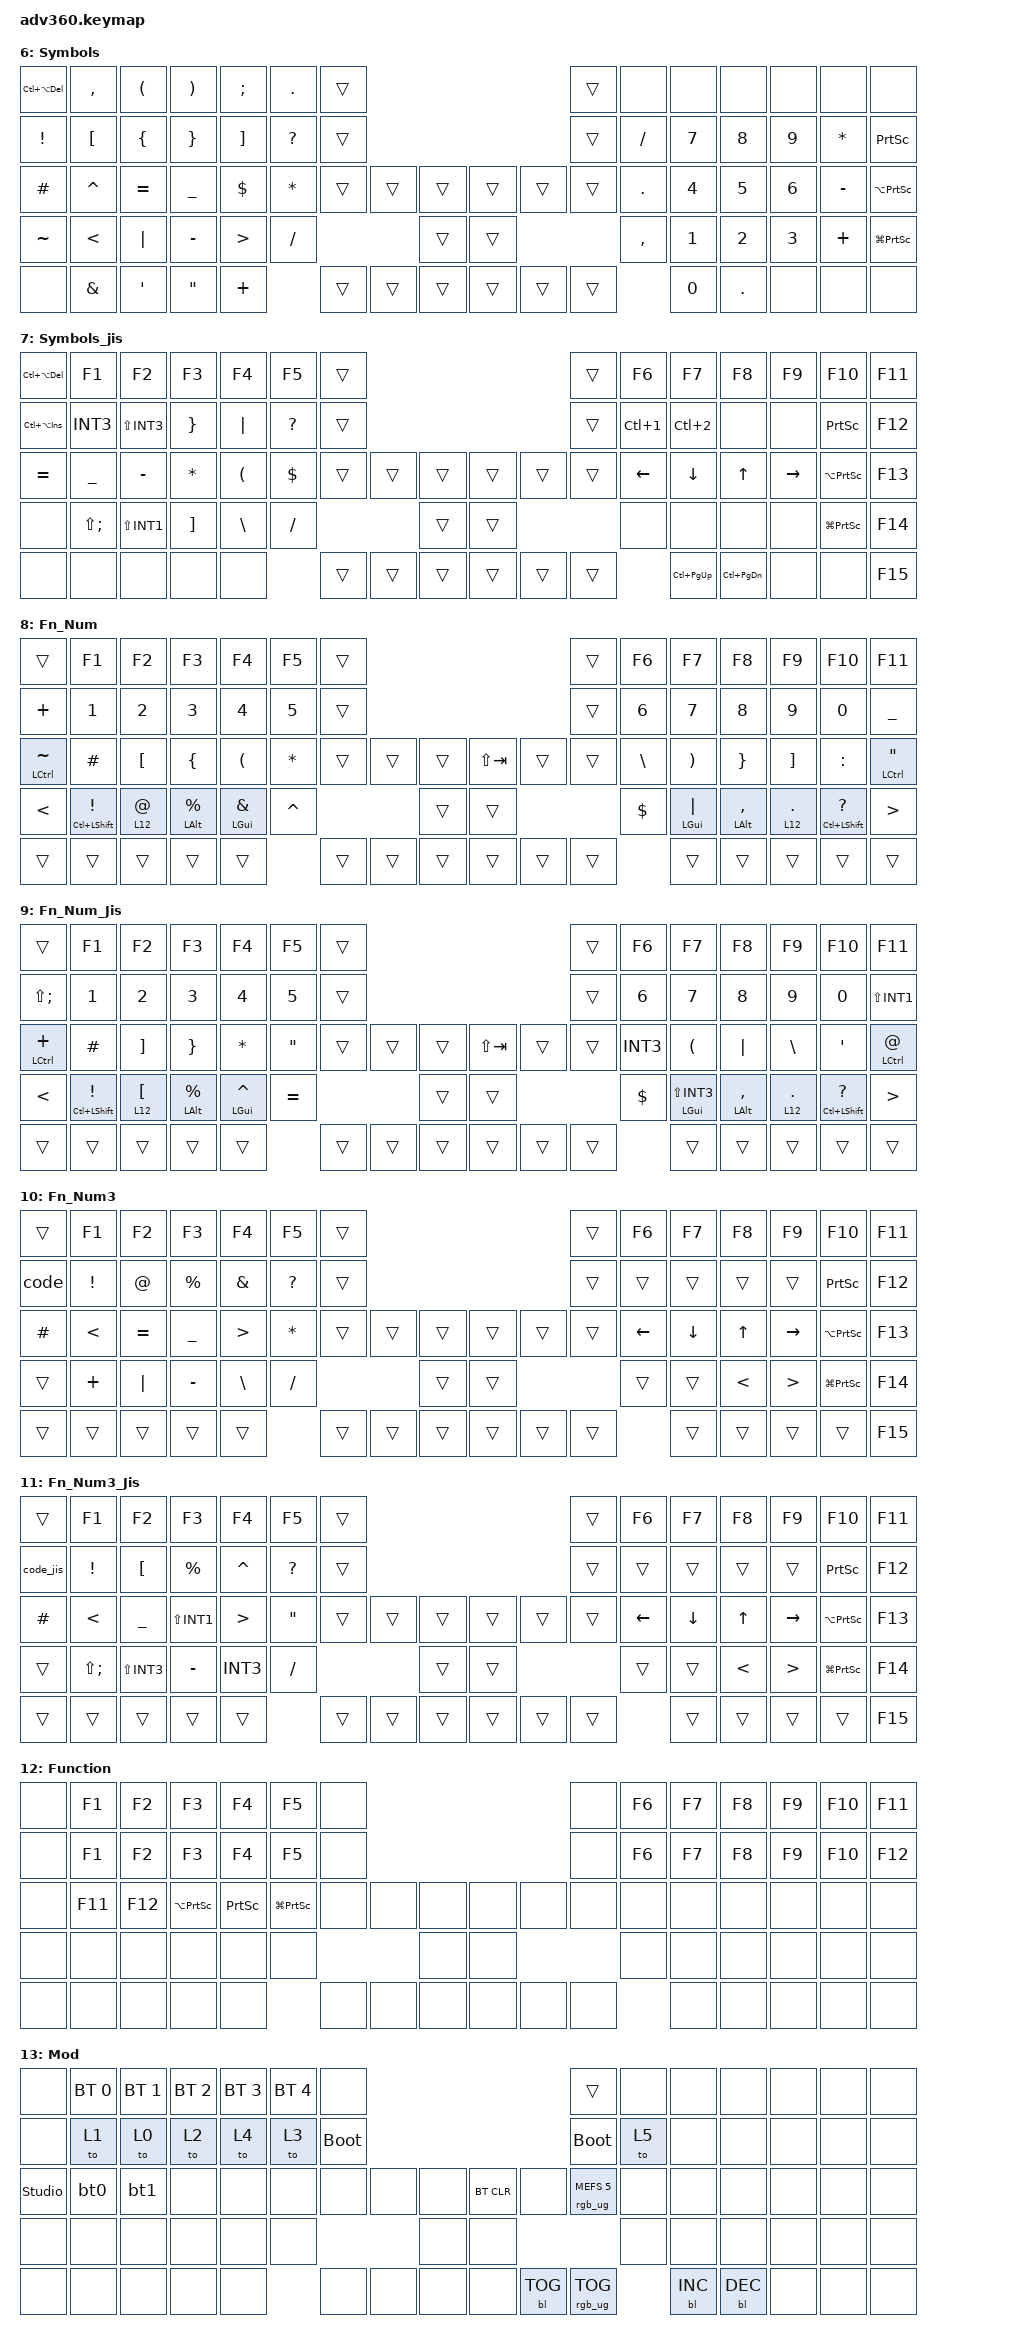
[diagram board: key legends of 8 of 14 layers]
#include <dt-bindings/zmk/stp.h>
#include <behaviors.dtsi>
#include <dt-bindings/zmk/backlight.h>
#include <dt-bindings/zmk/bt.h>
#include <dt-bindings/zmk/keys.h>
#include <dt-bindings/zmk/pointing.h>
#include <dt-bindings/zmk/rgb.h>

&sk {
    quick-release;
    release-after-ms = <300>;
};

/ {
    behaviors {
        #include "macros.dtsi"
      #include "version.dtsi"

        hml: hml {
            compatible = "zmk,behavior-hold-tap";
            label = "HML";
            bindings = <&kp>, <&kp>;

            #binding-cells = <2>;
            hold-trigger-key-positions = <7 8 9 10 11 12 13 21 22 23 24 25 26 27 37 38 39 40 41 42 43 44 45 53 54 55 56 57 58 59 68 69 70 71 72 73 74 75>;
            flavor = "balanced";
            hold-trigger-on-release;
            tapping-term-ms = <200>;
            require-prior-idle-ms = <150>;
            quick-tap-ms = <200>;
        };

        hmr: hmr {
            compatible = "zmk,behavior-hold-tap";
            label = "HMR";
            bindings = <&kp>, <&kp>;

            #binding-cells = <2>;
            flavor = "balanced";
            hold-trigger-on-release;
            tapping-term-ms = <200>;
            hold-trigger-key-positions = <0 1 2 3 4 5 6 14 15 16 17 18 19 20 28 29 30 31 32 33 34 35 36 46 47 48 49 50 51 52 60 61 62 63 64 65 66 67>;
            require-prior-idle-ms = <150>;
            quick-tap-ms = <200>;
        };

        hml_mod: hml_mod {
            compatible = "zmk,behavior-hold-tap";
            label = "HML_MOD";
            bindings = <&mo>, <&kp>;

            #binding-cells = <2>;
            hold-trigger-key-positions = <7 8 9 10 11 12 13 21 22 23 24 25 26 27 37 38 39 40 41 42 43 44 45 53 54 55 56 57 58 59 68 69 70 71 72 73 74 75>;
            flavor = "balanced";
            hold-trigger-on-release;
            tapping-term-ms = <280>;
            quick-tap-ms = <200>;
            require-prior-idle-ms = <150>;
        };

        hmr_mod: hmr_mod {
            compatible = "zmk,behavior-hold-tap";
            label = "HMR_MOD";
            bindings = <&mo>, <&kp>;

            #binding-cells = <2>;
            flavor = "balanced";
            hold-trigger-on-release;
            tapping-term-ms = <280>;
            hold-trigger-key-positions = <0 1 2 3 4 5 6 14 15 16 17 18 19 20 28 29 30 31 32 33 34 35 36 46 47 48 49 50 51 52 60 61 62 63 64 65 66 67>;
            quick-tap-ms = <200>;
            require-prior-idle-ms = <150>;
        };

        mj_bp: mj_bp {
            compatible = "zmk,behavior-mod-morph";
            label = "MJ_BP";
            bindings = <&kp INT3>, <&kp LS(INT3)>;

            #binding-cells = <0>;
            mods = <(MOD_LSFT|MOD_RSFT)>;
        };

        mj_mu: mj_mu {
            compatible = "zmk,behavior-mod-morph";
            label = "MJ_MU";
            bindings = <&kp MINUS>, <&kp LS(INT1)>;

            #binding-cells = <0>;
            mods = <(MOD_LSFT|MOD_RSFT)>;
        };

        mj_gt: mj_gt {
            compatible = "zmk,behavior-mod-morph";
            label = "MJ_GT";
            bindings = <&kp LBRC>, <&kp PLUS>;

            #binding-cells = <0>;
            mods = <(MOD_LSFT|MOD_RSFT)>;
        };

        mj_ep: mj_ep {
            compatible = "zmk,behavior-mod-morph";
            label = "MJ_EP";
            bindings = <&kp UNDER>, <&kp LS(SEMI)>;

            #binding-cells = <0>;
            mods = <(MOD_LSFT|MOD_RSFT)>;
        };

        mj_qd: mj_qd {
            compatible = "zmk,behavior-mod-morph";
            label = "MJ_QD";
            bindings = <&kp AMPS>, <&kp AT>;

            #binding-cells = <0>;
            mods = <(MOD_LSFT|MOD_RSFT)>;
        };

        mj_sc: mj_sc {
            compatible = "zmk,behavior-mod-morph";
            label = "MJ_SC";
            bindings = <&kp SEMI>, <&kp SQT>;

            #binding-cells = <0>;
            mods = <(MOD_LSFT|MOD_RSFT)>;
        };

        mm_n1: mm_n1 {
            compatible = "zmk,behavior-mod-morph";
            label = "MM_N1";
            bindings = <&kp HASH>, <&kp N1>;

            #binding-cells = <0>;
            mods = <(MOD_LSFT|MOD_RSFT)>;
        };

        mm_n2: mm_n2 {
            compatible = "zmk,behavior-mod-morph";
            label = "MM_N2";
            bindings = <&kp LBKT>, <&kp N2>;

            #binding-cells = <0>;
            mods = <(MOD_LSFT|MOD_RSFT)>;
        };

        mm_n3: mm_n3 {
            compatible = "zmk,behavior-mod-morph";
            label = "MM_N3";
            bindings = <&kp LBRC>, <&kp N3>;

            #binding-cells = <0>;
            mods = <(MOD_LSFT|MOD_RSFT)>;
        };

        mm_n4: mm_n4 {
            compatible = "zmk,behavior-mod-morph";
            label = "MM_N4";
            bindings = <&kp LPAR>, <&kp N4>;

            #binding-cells = <0>;
            mods = <(MOD_LSFT|MOD_RSFT)>;
        };

        mm_n5: mm_n5 {
            compatible = "zmk,behavior-mod-morph";
            label = "MM_N5";
            bindings = <&kp STAR>, <&kp N5>;

            #binding-cells = <0>;
            mods = <(MOD_LSFT|MOD_RSFT)>;
        };

        mm_n6: mm_n6 {
            compatible = "zmk,behavior-mod-morph";
            label = "MM_N6";
            bindings = <&kp CARET>, <&kp N6>;

            #binding-cells = <0>;
            mods = <(MOD_LSFT|MOD_RSFT)>;
        };

        mm_n7: mm_n7 {
            compatible = "zmk,behavior-mod-morph";
            label = "MM_N7";
            bindings = <&kp RPAR>, <&kp N7>;

            #binding-cells = <0>;
            mods = <(MOD_LSFT|MOD_RSFT)>;
        };

        mm_n8: mm_n8 {
            compatible = "zmk,behavior-mod-morph";
            label = "MM_N8";
            bindings = <&kp RBRC>, <&kp N8>;

            #binding-cells = <0>;
            mods = <(MOD_LSFT|MOD_RSFT)>;
        };

        mm_n9: mm_n9 {
            compatible = "zmk,behavior-mod-morph";
            label = "MM_N9";
            bindings = <&kp RBKT>, <&kp N9>;

            #binding-cells = <0>;
            mods = <(MOD_LSFT|MOD_RSFT)>;
        };

        mm_n0: mm_n0 {
            compatible = "zmk,behavior-mod-morph";
            label = "MM_N0";
            bindings = <&kp DLLR>, <&kp N0>;

            #binding-cells = <0>;
            mods = <(MOD_LSFT|MOD_RSFT)>;
        };

        mm_ea: mm_ea {
            compatible = "zmk,behavior-mod-morph";
            label = "MM_EA";
            bindings = <&kp EXCL>, <&kp AT>;

            #binding-cells = <0>;
            mods = <(MOD_LSFT|MOD_RSFT)>;
        };

        mm_pa: mm_pa {
            compatible = "zmk,behavior-mod-morph";
            label = "MM_PA";
            bindings = <&kp PRCNT>, <&kp AMPS>;

            #binding-cells = <0>;
            mods = <(MOD_LSFT|MOD_RSFT)>;
        };

        mj_n1: mj_n1 {
            compatible = "zmk,behavior-mod-morph";
            label = "MJ_N1";
            bindings = <&kp HASH>, <&kp N1>;

            #binding-cells = <0>;
            mods = <(MOD_LSFT|MOD_RSFT)>;
        };

        mj_n2: mj_n2 {
            compatible = "zmk,behavior-mod-morph";
            label = "MJ_N2";
            bindings = <&kp RBKT>, <&kp N2>;

            #binding-cells = <0>;
            mods = <(MOD_LSFT|MOD_RSFT)>;
        };

        mj_n3: mj_n3 {
            compatible = "zmk,behavior-mod-morph";
            label = "MJ_N3";
            bindings = <&kp RBRC>, <&kp N3>;

            #binding-cells = <0>;
            mods = <(MOD_LSFT|MOD_RSFT)>;
        };

        mj_n4: mj_n4 {
            compatible = "zmk,behavior-mod-morph";
            label = "MJ_N4";
            bindings = <&kp STAR>, <&kp N4>;

            #binding-cells = <0>;
            mods = <(MOD_LSFT|MOD_RSFT)>;
        };

        mj_n5: mj_n5 {
            compatible = "zmk,behavior-mod-morph";
            label = "MJ_N5";
            bindings = <&kp DQT>, <&kp N5>;

            #binding-cells = <0>;
            mods = <(MOD_LSFT|MOD_RSFT)>;
        };

        mj_n6: mj_n6 {
            compatible = "zmk,behavior-mod-morph";
            label = "MJ_N6";
            bindings = <&kp EQUAL>, <&kp N6>;

            #binding-cells = <0>;
            mods = <(MOD_LSFT|MOD_RSFT)>;
        };

        mj_n7: mj_n7 {
            compatible = "zmk,behavior-mod-morph";
            label = "MJ_N7";
            bindings = <&kp LPAR>, <&kp N7>;

            #binding-cells = <0>;
            mods = <(MOD_LSFT|MOD_RSFT)>;
        };

        mj_n8: mj_n8 {
            compatible = "zmk,behavior-mod-morph";
            label = "MJ_N8";
            bindings = <&kp PIPE>, <&kp N8>;

            #binding-cells = <0>;
            mods = <(MOD_LSFT|MOD_RSFT)>;
        };

        mj_n9: mj_n9 {
            compatible = "zmk,behavior-mod-morph";
            label = "MJ_N9";
            bindings = <&kp BSLH>, <&kp N9>;

            #binding-cells = <0>;
            mods = <(MOD_LSFT|MOD_RSFT)>;
        };

        mj_n0: mj_n0 {
            compatible = "zmk,behavior-mod-morph";
            label = "MJ_N0";
            bindings = <&kp DLLR>, <&kp N0>;

            #binding-cells = <0>;
            mods = <(MOD_LSFT|MOD_RSFT)>;
        };

        mj_ea: mj_ea {
            compatible = "zmk,behavior-mod-morph";
            label = "MJ_EA";
            bindings = <&kp EXCL>, <&kp LBKT>;

            #binding-cells = <0>;
            mods = <(MOD_LSFT|MOD_RSFT)>;
        };

        mj_pa: mj_pa {
            compatible = "zmk,behavior-mod-morph";
            label = "MJ_PA";
            bindings = <&kp PRCNT>, <&kp CARET>;

            #binding-cells = <0>;
            mods = <(MOD_LSFT|MOD_RSFT)>;
        };

        mtl: mtl {
            compatible = "zmk,behavior-hold-tap";
            label = "MTL";
            bindings = <&kp>, <&to>;

            #binding-cells = <2>;
            tapping-term-ms = <200>;
        };

        aj_n2: aj_n2 {
            compatible = "zmk,behavior-mod-morph";
            label = "AJ_N2";
            bindings = <&kp N2>, <&kp LBKT>;

            #binding-cells = <0>;
            mods = <(MOD_LSFT|MOD_RSFT)>;
        };

        aj_n6: aj_n6 {
            compatible = "zmk,behavior-mod-morph";
            label = "AJ_N6";
            bindings = <&kp N6>, <&kp EQUAL>;

            #binding-cells = <0>;
            mods = <(MOD_LSFT|MOD_RSFT)>;
        };

        aj_n7: aj_n7 {
            compatible = "zmk,behavior-mod-morph";
            label = "AJ_N7";
            bindings = <&kp N7>, <&kp CARET>;

            #binding-cells = <0>;
            mods = <(MOD_LSFT|MOD_RSFT)>;
        };

        aj_n8: aj_n8 {
            compatible = "zmk,behavior-mod-morph";
            label = "AJ_N8";
            bindings = <&kp N8>, <&kp DQT>;

            #binding-cells = <0>;
            mods = <(MOD_LSFT|MOD_RSFT)>;
        };

        aj_n9: aj_n9 {
            compatible = "zmk,behavior-mod-morph";
            label = "AJ_N9";
            bindings = <&kp N9>, <&kp STAR>;

            #binding-cells = <0>;
            mods = <(MOD_LSFT|MOD_RSFT)>;
        };

        aj_n0: aj_n0 {
            compatible = "zmk,behavior-mod-morph";
            label = "AJ_N0";
            bindings = <&kp N0>, <&kp LPAR>;

            #binding-cells = <0>;
            mods = <(MOD_LSFT|MOD_RSFT)>;
        };

        hml_mod2: hml_mod2 {
            compatible = "zmk,behavior-hold-tap";
            label = "HML_MOD2";
            bindings = <&mo>, <&kp>;

            #binding-cells = <2>;
            hold-trigger-key-positions = <7 8 9 10 11 12 13 21 22 23 24 25 26 27 37 38 39 40 41 42 43 44 45 53 54 55 56 57 58 59 68 69 70 71 72 73 74 75>;
            flavor = "balanced";
            hold-trigger-on-release;
            tapping-term-ms = <280>;
            quick-tap-ms = <175>;
            require-prior-idle-ms = <150>;
            hold-while-undecided;
        };

        hmr_mod2: hmr_mod2 {
            compatible = "zmk,behavior-hold-tap";
            label = "HMR_MOD2";
            bindings = <&mo>, <&kp>;

            #binding-cells = <2>;
            flavor = "balanced";
            hold-trigger-on-release;
            tapping-term-ms = <280>;
            hold-trigger-key-positions = <0 1 2 3 4 5 6 14 15 16 17 18 19 20 28 29 30 31 32 33 34 35 36 46 47 48 49 50 51 52 60 61 62 63 64 65 66 67>;
            quick-tap-ms = <175>;
            require-prior-idle-ms = <150>;
            hold-while-undecided;
        };

        hm: hm {
            compatible = "zmk,behavior-hold-tap";
            label = "HM";
            bindings = <&mo>, <&kp>;

            #binding-cells = <2>;
            hold-trigger-key-positions = <7 8 9 10 11 12 13 21 22 23 24 25 26 27 39 40 41 42 43 44 45 54 55 56 57 58 59 71 72 73 74 75 0 1 2 3 4 5 6 14 15 16 17 18 19 20 28 29 30 31 32 33 34 46 47 48 49 50 51 60 61 62 63 64>;
            tapping-term-ms = <200>;
            require-prior-idle-ms = <150>;
            flavor = "balanced";
            hold-trigger-on-release;
        };

        mm_lp: mm_lp {
            compatible = "zmk,behavior-mod-morph";
            label = "MM_LP";
            bindings = <&kp LT>, <&kp PRCNT>;

            #binding-cells = <0>;
            mods = <(MOD_LSFT|MOD_RSFT)>;
        };

        mm_ga: mm_ga {
            compatible = "zmk,behavior-mod-morph";
            label = "MM_GA";
            bindings = <&kp GT>, <&kp AMPS>;

            #binding-cells = <0>;
            mods = <(MOD_LSFT|MOD_RSFT)>;
        };

        mj_ga: mj_ga {
            compatible = "zmk,behavior-mod-morph";
            label = "MJ_GA";
            bindings = <&kp GT>, <&kp CARET>;

            #binding-cells = <0>;
            mods = <(MOD_LSFT|MOD_RSFT)>;
        };

        cc: cc {
            compatible = "zmk,behavior-mod-morph";
            label = "CC";
            bindings = <&kp COMMA>, <&kp COMMA>;

            #binding-cells = <0>;
            mods = <(MOD_LSFT|MOD_RSFT)>;
        };

        dd: dd {
            compatible = "zmk,behavior-mod-morph";
            label = "DD";
            bindings = <&kp DOT>, <&kp DOT>;

            #binding-cells = <0>;
            mods = <(MOD_LSFT|MOD_RSFT)>;
        };

        hmr_cc: hmr_cc {
            compatible = "zmk,behavior-hold-tap";
            label = "HMR_CC";
            bindings = <&kp>, <&cc>;

            #binding-cells = <2>;
            flavor = "balanced";
            hold-trigger-on-release;
            tapping-term-ms = <200>;
            hold-trigger-key-positions = <0 1 2 3 4 5 6 14 15 16 17 18 19 20 28 29 30 31 32 33 34 35 36 46 47 48 49 50 51 52 60 61 62 63 64 65 66 67>;
            require-prior-idle-ms = <150>;
            quick-tap-ms = <200>;
        };

        hmr_dd: hmr_dd {
            compatible = "zmk,behavior-hold-tap";
            label = "HMR_DD";
            bindings = <&kp>, <&dd>;

            #binding-cells = <2>;
            flavor = "balanced";
            hold-trigger-on-release;
            tapping-term-ms = <200>;
            hold-trigger-key-positions = <0 1 2 3 4 5 6 14 15 16 17 18 19 20 28 29 30 31 32 33 34 35 36 46 47 48 49 50 51 52 60 61 62 63 64 65 66 67>;
            require-prior-idle-ms = <150>;
            quick-tap-ms = <200>;
        };

        hmr_sc: hmr_sc {
            compatible = "zmk,behavior-hold-tap";
            label = "HMR_SC";
            bindings = <&kp>, <&mj_sc>;

            #binding-cells = <2>;
            flavor = "balanced";
            hold-trigger-on-release;
            tapping-term-ms = <200>;
            hold-trigger-key-positions = <0 1 2 3 4 5 6 14 15 16 17 18 19 20 28 29 30 31 32 33 34 35 36 46 47 48 49 50 51 52 60 61 62 63 64 65 66 67>;
            require-prior-idle-ms = <150>;
            quick-tap-ms = <200>;
        };

        custom_shift: custom_shift {
            compatible = "zmk,behavior-tap-dance";
            label = "CUSTOM_SHIFT";
            #binding-cells = <0>;
            bindings = <&sk LSHIFT>, <&caps_word>;
        };

        ins_com: ins_com {
            compatible = "zmk,behavior-mod-morph";
            label = "INS_COM";
            bindings = <&kp INS>, <&kp COMMA>;

            #binding-cells = <0>;
            mods = <(MOD_LSFT|MOD_RSFT)>;
        };

        del_dot: del_dot {
            compatible = "zmk,behavior-mod-morph";
            label = "DEL_DOT";
            bindings = <&kp DEL>, <&kp DOT>;

            #binding-cells = <0>;
            mods = <(MOD_LSFT|MOD_RSFT)>;
        };

        hml_gt: hml_gt {
            compatible = "zmk,behavior-hold-tap";
            label = "HML_GT";
            bindings = <&kp>, <&mj_gt>;

            #binding-cells = <2>;
            flavor = "balanced";
            hold-trigger-on-release;
            tapping-term-ms = <200>;
            require-prior-idle-ms = <150>;
            quick-tap-ms = <200>;
            hold-trigger-key-positions = <7 8 9 10 11 12 13 21 22 23 24 25 26 27 37 38 39 40 41 42 43 44 45 53 54 55 56 57 58 59 68 69 70 71 72 73 74 75>;
        };

        hmr_qd: hmr_qd {
            compatible = "zmk,behavior-hold-tap";
            label = "HMR_QD";
            bindings = <&kp>, <&mj_qd>;

            #binding-cells = <2>;
            flavor = "balanced";
            hold-trigger-on-release;
            tapping-term-ms = <200>;
            hold-trigger-key-positions = <0 1 2 3 4 5 6 14 15 16 17 18 19 20 28 29 30 31 32 33 34 35 36 46 47 48 49 50 51 52 60 61 62 63 64 65 66 67>;
            require-prior-idle-ms = <150>;
            quick-tap-ms = <200>;
        };

        up_lt: up_lt {
            compatible = "zmk,behavior-mod-morph";
            label = "UP_LT";
            bindings = <&kp UP>, <&kp LT>;

            #binding-cells = <0>;
            mods = <(MOD_LSFT|MOD_RSFT)>;
        };

        lc_gt: lc_gt {
            compatible = "zmk,behavior-mod-morph";
            label = "LC_GT";
            bindings = <&mkp LCLK>, <&kp GT>;

            #binding-cells = <0>;
            mods = <(MOD_LSFT|MOD_RSFT)>;
        };

        pgdn_prcnt: pgdn_prcnt {
            compatible = "zmk,behavior-mod-morph";
            label = "PGDN_PRCNT";
            bindings = <&kp PG_DN>, <&kp PRCNT>;

            #binding-cells = <0>;
            mods = <(MOD_LSFT|MOD_RSFT)>;
        };

        left_amps: left_amps {
            compatible = "zmk,behavior-mod-morph";
            label = "LEFT_AMPS";
            bindings = <&kp LEFT>, <&kp AMPS>;

            #binding-cells = <0>;
            mods = <(MOD_LSFT|MOD_RSFT)>;
        };

        mj_left_amps: mj_left_amps {
            compatible = "zmk,behavior-mod-morph";
            label = "MJ_LEFT_AMPS";
            bindings = <&kp LEFT>, <&kp CARET>;

            #binding-cells = <0>;
            mods = <(MOD_LSFT|MOD_RSFT)>;
        };
    };

    macros {
        bt0: bt0 {
            compatible = "zmk,behavior-macro";
            #binding-cells = <0>;
            bindings =
                <&macro_press>,
                <&kp F13>,
                <&macro_release>,
                <&macro_wait_time 50>,
                <&macro_press>,
                <&bt BT_SEL 0>,
                <&macro_release>;

            label = "BT0";
        };

        bt1: bt1 {
            compatible = "zmk,behavior-macro";
            #binding-cells = <0>;
            bindings =
                <&macro_press>,
                <&kp F14>,
                <&macro_release>,
                <&macro_wait_time 50>,
                <&macro_press>,
                <&bt BT_SEL 1>,
                <&macro_release>;

            label = "BT1";
        };

        code: code {
            compatible = "zmk,behavior-macro";
            #binding-cells = <0>;
            bindings = <&kp GRAVE &kp GRAVE &kp GRAVE>;
            label = "CODE";
        };

        code_jis: code_jis {
            compatible = "zmk,behavior-macro";
            #binding-cells = <0>;
            bindings = <&kp LBRC &kp LBRC &kp LBRC>;
            label = "CODE_JIS";
        };

        d_colon: double_colon {
            compatible = "zmk,behavior-macro";
            #binding-cells = <0>;
            bindings = <&kp COLON &kp COLON>;
            label = "DOUBLE_COLON";
        };

        d_colon_jis: double_colon_jis {
            compatible = "zmk,behavior-macro";
            #binding-cells = <0>;
            bindings = <&kp SQT &kp SQT>;
            label = "DOUBLE_COLON_JIS";
        };

        pren: pren {
            compatible = "zmk,behavior-macro";
            #binding-cells = <0>;
            bindings = <&kp LPAR &kp RPAR>;
            label = "PREN";
        };

        pren_jis: pren_jis {
            compatible = "zmk,behavior-macro";
            #binding-cells = <0>;
            bindings = <&kp STAR &kp LPAR>;
            label = "PREN_JIS";
        };

        brc: brc {
            compatible = "zmk,behavior-macro";
            #binding-cells = <0>;
            bindings = <&kp LBRC &kp RBRC>;
            label = "BRC";
        };

        brc_jis: brc_jis {
            compatible = "zmk,behavior-macro";
            #binding-cells = <0>;
            bindings = <&kp RBRC &kp PIPE>;
            label = "BRC_JIS";
        };

        bkt: bkt {
            compatible = "zmk,behavior-macro";
            #binding-cells = <0>;
            bindings = <&kp LBKT &kp RBKT>;
            label = "BKT";
        };

        bkt_jis: bkt_jis {
            compatible = "zmk,behavior-macro";
            #binding-cells = <0>;
            bindings = <&kp RBKT &kp BSLH>;
            label = "BKT_JIS";
        };
    };

    combos { compatible = "zmk,combos"; };

    keymap {
        compatible = "zmk,keymap";

        base_reverse_org {
            display-name = "Base_reverse_Org";
            bindings = <
&mm_ea            &mm_n1             &mm_n2                    &mm_n3       &mm_n4       &mm_n5         &kp PSCRN                                                              &mo 13     &mm_n6         &mm_n7       &mm_n8           &mm_n9                      &mm_n0                &kp BSLH
&kp EQUAL         &kp Q              &kp W                     &kp E        &kp R        &kp T          &kp INS                                                                &kp DEL    &kp Y          &kp U        &kp I            &kp O                       &kp P                 &kp MINUS
&hml LCTRL GRAVE  &kp A              &kp S                     &kp D        &kp F        &kp G          &none      &kp LCTRL  &kp LALT       &kp TAB                &kp ESC    &none      &kp H          &kp J        &kp K            &kp L                       &kp SEMI              &hmr LCTRL SQT
&custom_shift     &hml LC(LSHIFT) Z  &hml LS(LA(LG(LCTRL))) X  &hml LALT C  &hml LGUI V  &hml_mod 12 B                        &kp LGUI       &kp LS(LA(LG(LCTRL)))                        &hmr_mod 12 N  &hmr LGUI M  &hmr LALT COMMA  &hmr LS(LA(LG(LCTRL))) DOT  &hmr LC(LSHIFT) FSLH  &custom_shift
&mo 12            &kp PG_UP          &kp PAGE_DOWN             &kp LEFT     &kp RIGHT                   &kp BSPC   &mo 8      &kp LANG2      &kp LANG1              &kp ENTER  &kp SPACE                 &kp DOWN     &up_lt           &lc_gt                      &mkp RCLK             &mo 12
            >;
        };

        base_reverse {
            display-name = "Base_reverse";
            bindings = <
&mm_ea            &mm_n1         &mm_n2       &mm_n3      &mm_n4     &mm_n5  &kp PSCRN                                                                  &mo 13     &mm_n6  &mm_n7    &mm_n8  &mm_n9  &mm_n0            &kp BSLH
&kp EQUAL         &kp Q          &kp W        &kp E       &kp R      &kp T   &kp INS                                                                    &kp DEL    &kp Y   &kp U     &kp I   &kp O   &kp P             &kp MINUS
&hml LCTRL GRAVE  &kp A          &kp S        &kp D       &kp F      &kp G   &kp LT     &kp LCTRL      &kp LALT       &kp TAB                &kp ESC    &kp GT     &kp H   &kp J     &kp K   &kp L   &kp SEMI          &hmr LCTRL SQT
&custom_shift     &hml LSHIFT Z  &kp X        &kp C       &kp V      &kp B                             &kp LGUI       &kp LS(LA(LG(LCTRL)))                        &kp N   &kp M     &cc     &dd     &hmr LSHIFT FSLH  &custom_shift
&mo 12            &kp PG_UP      &pgdn_prcnt  &left_amps  &kp RIGHT          &kp BSPC   &custom_shift  &kp LANG2      &kp LANG1              &kp ENTER  &kp SPACE          &kp DOWN  &up_lt  &lc_gt  &mkp RCLK         &mo 12
            >;
        };

        default_layer {
            display-name = "Base";
            bindings = <
&kp DEL           &kp N1             &kp N2                    &kp N3       &kp N4       &kp N5         &kp PSCRN                                                              &mo 13     &kp N6         &kp N7       &kp N8           &kp N9                      &kp N0                &kp BSLH
&kp EQUAL         &kp Q              &kp W                     &kp E        &kp R        &kp T          &kp INS                                                                &kp DEL    &kp Y          &kp U        &kp I            &kp O                       &kp P                 &kp MINUS
&hml LCTRL GRAVE  &kp A              &kp S                     &kp D        &kp F        &kp G          &none      &kp LCTRL  &kp LALT       &kp TAB                &kp ESC    &none      &kp H          &kp J        &kp K            &kp L                       &kp SEMI              &hmr LCTRL SQT
&custom_shift     &hml LC(LSHIFT) Z  &hml LS(LA(LG(LCTRL))) X  &hml LALT C  &hml LGUI V  &hml_mod 12 B                        &kp LGUI       &kp LS(LA(LG(LCTRL)))                        &hmr_mod 12 N  &hmr LGUI M  &hmr LALT COMMA  &hmr LS(LA(LG(LCTRL))) DOT  &hmr LC(LSHIFT) FSLH  &custom_shift
&mo 12            &kp PG_UP          &kp PG_DN                 &kp LEFT     &kp RIGHT                   &kp BSPC   &mo 8      &kp LANG2      &kp LANG1              &kp ENTER  &kp SPACE                 &kp DOWN     &up_lt           &lc_gt                      &mkp RCLK             &mo 12
            >;
        };

        jis_reverse_org {
            display-name = "Jisa_Reverse_Org";
            bindings = <
&mj_ea           &mj_n1             &mj_n2                    &mj_n3       &mj_n4       &mj_n5         &kp PSCRN                                                              &mo 13     &mj_n6         &mj_n7       &mj_n8           &mj_n9                      &mj_n0                &mj_bp
&mj_ep           &kp Q              &kp W                     &kp E        &kp R        &kp T          &kp INS                                                                &kp DEL    &kp Y          &kp U        &kp I            &kp O                       &kp P                 &mj_mu
&hml_gt LCTRL 0  &kp A              &kp S                     &kp D        &kp F        &kp G          &none      &kp LCTRL  &kp LALT       &kp TAB                &kp ESC    &none      &kp H          &kp J        &kp K            &kp L                       &kp SEMI              &hmr_qd LCTRL 0
&custom_shift    &hml LC(LSHIFT) Z  &hml LS(LA(LG(LCTRL))) X  &hml LALT C  &hml LGUI V  &hml_mod 12 B                        &kp LGUI       &kp LS(LA(LG(LCTRL)))                        &hmr_mod 12 N  &hmr LGUI M  &hmr LALT COMMA  &hmr LS(LA(LG(LCTRL))) DOT  &hmr LC(LSHIFT) FSLH  &custom_shift
&mo 12           &kp PG_UP          &kp PAGE_DOWN             &kp LEFT     &kp RIGHT                   &kp BSPC   &mo 9      &kp LANG2      &kp LANG1              &kp ENTER  &kp SPACE                 &kp DOWN     &kp UP           &mkp LCLK                   &mkp RCLK             &mo 12
            >;
        };

        jis_reverse {
            display-name = "Jisa_Reverse";
            bindings = <
&mj_ea           &mj_n1         &mj_n2       &mj_n3         &mj_n4     &mj_n5  &kp PSCRN                                                                  &mo 13     &mj_n6  &mj_n7    &mj_n8  &mj_n9  &mj_n0            &mj_bp
&mj_ep           &kp Q          &kp W        &kp E          &kp R      &kp T   &kp INS                                                                    &kp DEL    &kp Y   &kp U     &kp I   &kp O   &kp P             &mj_mu
&hml_gt LCTRL 0  &kp A          &kp S        &kp D          &kp F      &kp G   &kp LT     &kp LCTRL      &kp LALT       &kp TAB                &kp ESC    &kp GT     &kp H   &kp J     &kp K   &kp L   &kp SEMI          &hmr_qd LCTRL 0
&custom_shift    &hml LSHIFT Z  &kp X        &kp C          &kp V      &kp B                             &kp LGUI       &kp LS(LA(LG(LCTRL)))                        &kp N   &kp M     &cc     &dd     &hmr LSHIFT FSLH  &custom_shift
&mo 12           &kp PG_UP      &pgdn_prcnt  &mj_left_amps  &kp RIGHT          &kp BSPC   &custom_shift  &kp LANG2      &kp LANG1              &kp ENTER  &kp SPACE          &kp DOWN  &up_lt  &lc_gt  &mkp RCLK         &mo 12
            >;
        };

        jis {
            display-name = "Jis";
            bindings = <
&kp DEL          &kp N1             &aj_n2                    &kp N3       &kp N4       &kp N5         &kp PSCRN                                                              &mo 13     &aj_n6         &aj_n7       &aj_n8           &aj_n9                      &aj_n0                &mj_bp
&mj_ep           &kp Q              &kp W                     &kp E        &kp R        &kp T          &kp INS                                                                &kp DEL    &kp Y          &kp U        &kp I            &kp O                       &kp P                 &mj_mu
&hml_gt LCTRL 0  &kp A              &kp S                     &kp D        &kp F        &kp G          &none      &kp LCTRL  &kp LALT       &kp TAB                &kp ESC    &none      &kp H          &kp J        &kp K            &kp L                       &kp SEMI              &hmr_qd LCTRL 0
&custom_shift    &hml LC(LSHIFT) Z  &hml LS(LA(LG(LCTRL))) X  &hml LALT C  &hml LGUI V  &hml_mod 12 B                        &kp LGUI       &kp LS(LA(LG(LCTRL)))                        &hmr_mod 12 N  &hmr LGUI M  &hmr LALT COMMA  &hmr LS(LA(LG(LCTRL))) DOT  &hmr LC(LSHIFT) FSLH  &custom_shift
&mo 12           &kp PG_UP          &kp PG_DN                 &kp LEFT     &kp RIGHT                   &kp BSPC   &mo 9      &kp LANG2      &kp LANG1              &kp ENTER  &kp SPACE                 &kp DOWN     &kp UP           &kp RBKT                    &kp NON_US_BSLH       &mo 12
            >;
        };

        symbols {
            bindings = <
&kp LC(LA(DEL))  &kp COMMA  &kp LPAR   &kp RPAR   &kp SEMI    &kp DOT       &trans                                      &trans  &none      &none   &none    &none   &none      &none
&kp EXCL         &kp LBKT   &kp LBRC   &kp RBRC   &kp RBKT    &kp QUESTION  &trans                                      &trans  &kp FSLH   &kp N7  &kp N8   &kp N9  &kp STAR   &kp PSCRN
&kp HASH         &kp CARET  &kp EQUAL  &kp UNDER  &kp DOLLAR  &kp STAR      &trans  &trans  &trans      &trans  &trans  &trans  &kp DOT    &kp N4  &kp N5   &kp N6  &kp MINUS  &kp LA(PSCRN)
&kp TILDE        &kp LT     &kp PIPE   &kp MINUS  &kp GT      &kp FSLH                      &trans      &trans                  &kp COMMA  &kp N1  &kp N2   &kp N3  &kp PLUS   &kp LG(PSCRN)
&none            &kp AMPS   &kp SQT    &kp DQT    &kp PLUS                  &trans  &trans  &trans      &trans  &trans  &trans             &kp N0  &kp DOT  &none   &none      &none
            >;

            label = "Symbols";
        };

        symbols_jis {
            bindings = <
&kp LC(LA(DEL))  &kp F1        &kp F2        &kp F3    &kp F4    &kp F5        &trans                                      &trans  &kp F6      &kp F7         &kp F8         &kp F9     &kp F10        &kp F11
&kp LC(LA(INS))  &kp INT3      &kp LS(INT3)  &kp RBRC  &kp PIPE  &kp QUESTION  &trans                                      &trans  &kp LC(N1)  &kp LC(N2)     &none          &none      &kp PSCRN      &kp F12
&kp EQUAL        &kp UNDER     &kp MINUS     &kp STAR  &kp LPAR  &kp DLLR      &trans  &trans  &trans      &trans  &trans  &trans  &kp LEFT    &kp DOWN       &kp UP         &kp RIGHT  &kp LA(PSCRN)  &kp F13
&none            &kp LS(SEMI)  &kp LS(INT1)  &kp RBKT  &kp BSLH  &kp FSLH                      &trans      &trans                  &none       &none          &none          &none      &kp LG(PSCRN)  &kp F14
&none            &none         &none         &none     &none                   &trans  &trans  &trans      &trans  &trans  &trans              &kp LC(PG_UP)  &kp LC(PG_DN)  &none      &none          &kp F15
            >;

            label = "Symbols_jis";
        };

        fn_num {
            bindings = <
&trans            &kp F1                &kp F2          &kp F3           &kp F4          &kp F5     &trans                                           &trans  &kp F6    &kp F7          &kp F8           &kp F9           &kp F10                &kp F11
&kp PLUS          &kp N1                &kp N2          &kp N3           &kp N4          &kp N5     &trans                                           &trans  &kp N6    &kp N7          &kp N8           &kp N9           &kp N0                 &kp UNDER
&hml LCTRL TILDE  &kp HASH              &kp LBKT        &kp LBRC         &kp LPAR        &kp STAR   &trans  &trans  &trans      &kp LS(TAB)  &trans  &trans  &kp BSLH  &kp RPAR        &kp RBRC         &kp RBKT         &kp COLON              &hmr LCTRL DQT
&kp LT            &hml LC(LSHIFT) EXCL  &hml_mod 12 AT  &hml LALT PRCNT  &hml LGUI AMPS  &kp CARET                  &trans      &trans                       &kp DLLR  &hmr LGUI PIPE  &hmr LALT COMMA  &hmr_mod 12 DOT  &hmr LC(LSHIFT) QMARK  &kp GT
&trans            &trans                &trans          &trans           &trans                     &trans  &trans  &trans      &trans       &trans  &trans            &trans          &trans           &trans           &trans                 &trans
            >;

            label = "Fn_Num";
        };

        fn_num_jis {
            bindings = <
&trans           &kp F1                &kp F2            &kp F3           &kp F4           &kp F5     &trans                                           &trans  &kp F6    &kp F7              &kp F8           &kp F9           &kp F10                &kp F11
&kp LS(SEMI)     &kp N1                &kp N2            &kp N3           &kp N4           &kp N5     &trans                                           &trans  &kp N6    &kp N7              &kp N8           &kp N9           &kp N0                 &kp LS(INT1)
&hml LCTRL PLUS  &kp HASH              &kp RBKT          &kp RBRC         &kp STAR         &kp DQT    &trans  &trans  &trans      &kp LS(TAB)  &trans  &trans  &kp INT3  &kp LPAR            &kp PIPE         &kp BSLH         &kp SQT                &hmr LCTRL AT
&kp LT           &hml LC(LSHIFT) EXCL  &hml_mod 12 LBKT  &hml LALT PRCNT  &hml LGUI CARET  &kp EQUAL                  &trans      &trans                       &kp DLLR  &hmr LGUI LS(INT3)  &hmr LALT COMMA  &hmr_mod 12 DOT  &hmr LC(LSHIFT) QMARK  &kp GT
&trans           &trans                &trans            &trans           &trans                      &trans  &trans  &trans      &trans       &trans  &trans            &trans              &trans           &trans           &trans                 &trans
            >;

            label = "Fn_Num_Jis";
        };

        fn_num3 {
            label = "Fn_Num3";
            bindings = <
&trans    &kp F1    &kp F2     &kp F3     &kp F4    &kp F5     &trans                                      &trans  &kp F6    &kp F7    &kp F8  &kp F9     &kp F10        &kp F11
&code     &kp EXCL  &kp AT     &kp PRCNT  &kp AMPS  &kp QMARK  &trans                                      &trans  &trans    &trans    &trans  &trans     &kp PSCRN      &kp F12
&kp HASH  &kp LT    &kp EQUAL  &kp UNDER  &kp GT    &kp STAR   &trans  &trans  &trans      &trans  &trans  &trans  &kp LEFT  &kp DOWN  &kp UP  &kp RIGHT  &kp LA(PSCRN)  &kp F13
&trans    &kp PLUS  &kp PIPE   &kp MINUS  &kp BSLH  &kp FSLH                   &trans      &trans                  &trans    &trans    &kp LT  &kp GT     &kp LG(PSCRN)  &kp F14
&trans    &trans    &trans     &trans     &trans               &trans  &trans  &trans      &trans  &trans  &trans            &trans    &trans  &trans     &trans         &kp F15
            >;
        };

        fn_num3_jis {
            label = "Fn_Num3_Jis";
            bindings = <
&trans     &kp F1        &kp F2        &kp F3        &kp F4     &kp F5     &trans                                      &trans  &kp F6    &kp F7    &kp F8  &kp F9     &kp F10        &kp F11
&code_jis  &kp EXCL      &kp LBKT      &kp PRCNT     &kp CARET  &kp QMARK  &trans                                      &trans  &trans    &trans    &trans  &trans     &kp PSCRN      &kp F12
&kp HASH   &kp LT        &kp UNDER     &kp LS(INT1)  &kp GT     &kp DQT    &trans  &trans  &trans      &trans  &trans  &trans  &kp LEFT  &kp DOWN  &kp UP  &kp RIGHT  &kp LA(PSCRN)  &kp F13
&trans     &kp LS(SEMI)  &kp LS(INT3)  &kp MINUS     &kp INT3   &kp FSLH                   &trans      &trans                  &trans    &trans    &kp LT  &kp GT     &kp LG(PSCRN)  &kp F14
&trans     &trans        &trans        &trans        &trans                &trans  &trans  &trans      &trans  &trans  &trans            &trans    &trans  &trans     &trans         &kp F15
            >;
        };

        function {
            bindings = <
&none  &kp F1   &kp F2   &kp F3         &kp F4     &kp F5         &none                                  &none  &kp F6  &kp F7  &kp F8  &kp F9  &kp F10  &kp F11
&none  &kp F1   &kp F2   &kp F3         &kp F4     &kp F5         &none                                  &none  &kp F6  &kp F7  &kp F8  &kp F9  &kp F10  &kp F12
&none  &kp F11  &kp F12  &kp LA(PSCRN)  &kp PSCRN  &kp LG(PSCRN)  &none  &none  &none      &none  &none  &none  &none   &none   &none   &none   &none    &none
&none  &none    &none    &none          &none      &none                        &none      &none                &none   &none   &none   &none   &none    &none
&none  &none    &none    &none          &none                     &none  &none  &none      &none  &none  &none          &none   &none   &none   &none    &none
            >;

            label = "Function";
        };

        mod {
            display-name = "Mod";
            bindings = <
&none           &bt BT_SEL 0  &bt BT_SEL 1  &bt BT_SEL 2  &bt BT_SEL 3  &bt BT_SEL 4  &none                                                  &trans                  &none  &none       &none       &none  &none  &none
&none           &to 1         &to 0         &to 2         &to 4         &to 3         &bootloader                                            &bootloader             &to 5  &none       &none       &none  &none  &none
&studio_unlock  &bt0          &bt1          &none         &none         &none         &none        &none  &none      &bt BT_CLR  &none       &rgb_ug RGB_MEFS_CMD 5  &none  &none       &none       &none  &none  &none
&none           &none         &none         &none         &none         &none                             &none      &none                                           &none  &none       &none       &none  &none  &none
&none           &none         &none         &none         &none                       &none        &none  &none      &none       &bl BL_TOG  &rgb_ug RGB_TOG                &bl BL_INC  &bl BL_DEC  &none  &none  &none
            >;
        };
    };
};
